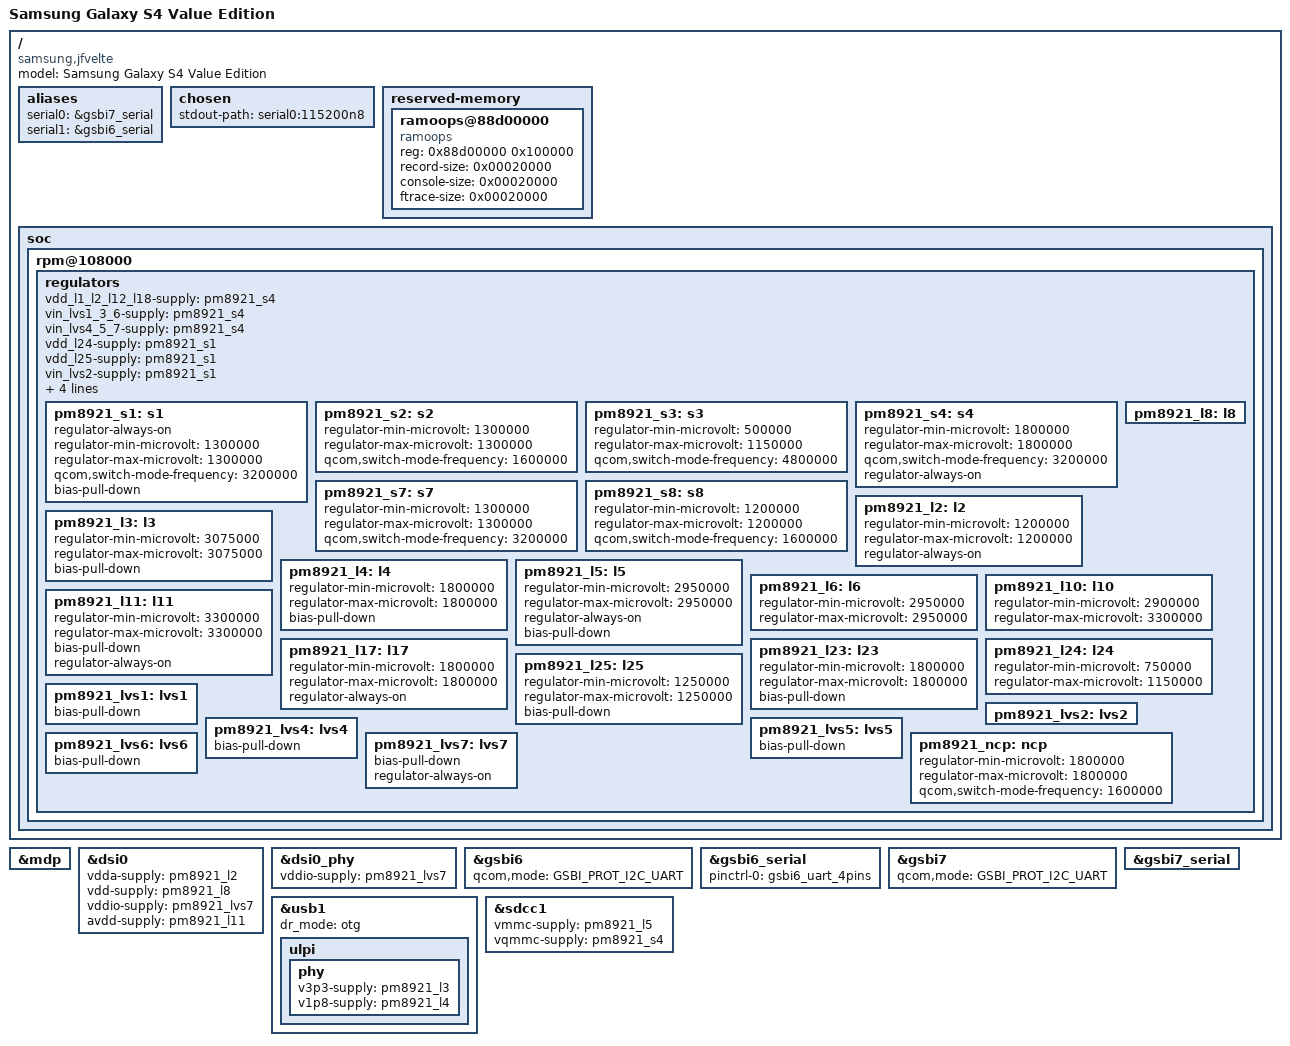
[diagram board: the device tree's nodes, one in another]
// SPDX-License-Identifier: GPL-2.0-only
#include <dt-bindings/gpio/gpio.h>
#include <dt-bindings/input/input.h>
#include <dt-bindings/pinctrl/qcom,pmic-gpio.h>

#include "qcom-apq8064-v2.0.dtsi"
#include "pm8821.dtsi"
#include "pm8921.dtsi"
/ {
	model = "Samsung Galaxy S4 Value Edition";
	compatible = "samsung,jfvelte", "qcom,apq8064";

	aliases {
		serial0 = &gsbi7_serial;
		serial1 = &gsbi6_serial;
	};

	chosen {
		stdout-path = "serial0:115200n8";
	};

	reserved-memory {
		#address-cells = <1>;
		#size-cells = <1>;
		ranges;

		ramoops@88d00000{
			compatible = "ramoops";
			reg = <0x88d00000 0x100000>;
			record-size     = <0x00020000>;
			console-size    = <0x00020000>;
			ftrace-size     = <0x00020000>;
		};
	};

	soc {
		rpm@108000 {
			regulators {
				vdd_l1_l2_l12_l18-supply = <&pm8921_s4>;
				vin_lvs1_3_6-supply = <&pm8921_s4>;
				vin_lvs4_5_7-supply = <&pm8921_s4>;


				vdd_l24-supply = <&pm8921_s1>;
				vdd_l25-supply = <&pm8921_s1>;
				vin_lvs2-supply = <&pm8921_s1>;

				vdd_l26-supply = <&pm8921_s7>;
				vdd_l27-supply = <&pm8921_s7>;
				vdd_l28-supply = <&pm8921_s7>;

				vdd_ncp-supply = <&pm8921_l6>;

				/* Buck SMPS */
				pm8921_s1: s1 {
					regulator-always-on;
					regulator-min-microvolt = <1300000>;
					regulator-max-microvolt = <1300000>;
					qcom,switch-mode-frequency = <3200000>;
					bias-pull-down;
				};

				/* wcnss_wlan.0-iris_vddrfa */
				pm8921_s2: s2 {
					regulator-min-microvolt = <1300000>;
					regulator-max-microvolt = <1300000>;
					qcom,switch-mode-frequency = <1600000>;
				};

				/*
				 * msm otg HSUSB_VDDCX
				 * wcnss_wlan.0-riva_vddcx
				 */
				pm8921_s3: s3 {
					regulator-min-microvolt = <500000>;
					regulator-max-microvolt = <1150000>;
					qcom,switch-mode-frequency = <4800000>;
				};

				/*
				 * msm_sdcc.1-sdc-vdd_io
				 * tabla2x-slim-CDC_VDDA_RX
				 * tabla2x-slim-CDC_VDDA_TX
				 * tabla2x-slim-CDC_VDD_CP
				 * tabla2x-slim-VDDIO_CDC
				 * wcnss_wlan.0-riva_vddpx
				 */
				pm8921_s4: s4 {
					regulator-min-microvolt	= <1800000>;
					regulator-max-microvolt	= <1800000>;
					qcom,switch-mode-frequency = <3200000>;
					regulator-always-on;
				};

				pm8921_s7: s7 {
					regulator-min-microvolt = <1300000>;
					regulator-max-microvolt = <1300000>;
					qcom,switch-mode-frequency = <3200000>;
				};

				pm8921_s8: s8 {
					regulator-min-microvolt = <1200000>;
					regulator-max-microvolt = <1200000>;
					qcom,switch-mode-frequency = <1600000>;
				};

				/* mipi_dsi.1-dsi1_pll_vdda */
				pm8921_l2: l2 {
					regulator-min-microvolt = <1200000>;
					regulator-max-microvolt = <1200000>;
					regulator-always-on;
				};

				/* msm_otg-HSUSB_3p3 */
				pm8921_l3: l3 {
					regulator-min-microvolt = <3075000>;
					regulator-max-microvolt = <3075000>;
					bias-pull-down;
				};

				/*
				 * msm_otg-HSUSB_1p8
				 * wcnss_wlan.0-iris_vddxo
				 */
				pm8921_l4: l4 {
					regulator-min-microvolt = <1800000>;
					regulator-max-microvolt = <1800000>;
					bias-pull-down;
				};

				/* msm_sdcc.1-sdc_vdd */
				pm8921_l5: l5 {
					regulator-min-microvolt = <2950000>;
					regulator-max-microvolt = <2950000>;
					regulator-always-on;
					bias-pull-down;
				};

				pm8921_l6: l6 {
					regulator-min-microvolt = <2950000>;
					regulator-max-microvolt = <2950000>;
				};

				pm8921_l8: l8 {};

				/* wcnss_wlan.0-iris_vddpa */
				pm8921_l10: l10 {
					regulator-min-microvolt = <2900000>;
					regulator-max-microvolt = <3300000>;
				};

				/* mipi_dsi.1-dsi1_avdd */
				pm8921_l11: l11 {
					regulator-min-microvolt = <3300000>;
					regulator-max-microvolt = <3300000>;
					bias-pull-down;
					regulator-always-on;
				};

				/* pwm_power for backlight */
				pm8921_l17: l17 {
					regulator-min-microvolt = <1800000>;
					regulator-max-microvolt = <1800000>;
					regulator-always-on;
				};

				/* camera, qdsp6 */
				pm8921_l23: l23 {
					regulator-min-microvolt = <1800000>;
					regulator-max-microvolt = <1800000>;
					bias-pull-down;
				};

				/* wcnss_wlan.0-riva_vddmx */
				pm8921_l24: l24 {
					regulator-min-microvolt = <750000>;
					regulator-max-microvolt = <1150000>;
				};

				/*
				 * tabla2x-slim-CDC_VDDA_A_1P2V
				 * tabla2x-slim-VDDD_CDC_D
				 */
				pm8921_l25: l25 {
					regulator-min-microvolt = <1250000>;
					regulator-max-microvolt = <1250000>;
					bias-pull-down;
				};

				/* wcnss_wlan.0-iris_vddio */
				pm8921_lvs1: lvs1 {
					bias-pull-down;
				};

				/* wcnss_wlan.0-iris_vdddig */
				pm8921_lvs2: lvs2 {
				};

				pm8921_lvs4: lvs4 {
					bias-pull-down;
				};

				pm8921_lvs5: lvs5 {
					bias-pull-down;
				};

				pm8921_lvs6: lvs6 {
					bias-pull-down;
				};
				/*
				 * mipi_dsi.1-dsi1_vddio
				 * pil_riva-pll_vdd
				 */
				pm8921_lvs7: lvs7 {
					bias-pull-down;
					regulator-always-on;
				};

				pm8921_ncp: ncp {
					regulator-min-microvolt = <1800000>;
					regulator-max-microvolt = <1800000>;
					qcom,switch-mode-frequency = <1600000>;
				};
			};
		};
	};
};

&mdp {
	status = "okay";
};

&dsi0 {
	status = "okay";
	vdda-supply = <&pm8921_l2>; /*VDD_MIPI1 to 4*/
	vdd-supply = <&pm8921_l8>;
	vddio-supply = <&pm8921_lvs7>;
	avdd-supply = <&pm8921_l11>;
};

&dsi0_phy {
	status = "okay";
	vddio-supply = <&pm8921_lvs7>; /*VDD_PLL2_1 to 7*/
};

&gsbi6 {
	status = "okay";
	qcom,mode = <GSBI_PROT_I2C_UART>;
};

&gsbi6_serial {
	status = "okay";

	pinctrl-names = "default";
	pinctrl-0 = <&gsbi6_uart_4pins>;
};

&gsbi7 {
	status = "okay";
	qcom,mode = <GSBI_PROT_I2C_UART>;
};

&gsbi7_serial {
	status = "okay";
};

/* OTG */
&usb1 {
	status = "okay";
	dr_mode = "otg";
	ulpi {
		phy {
			v3p3-supply = <&pm8921_l3>;
			v1p8-supply = <&pm8921_l4>;
		};
	};
};

/* eMMC */
&sdcc1 {
	status = "okay";
	vmmc-supply = <&pm8921_l5>;
	vqmmc-supply = <&pm8921_s4>;
};
